# RZT2L register map
Vendor: Renesas Electronics Corporation; Series: RZT; File version: 1.20.00
CPU: other r0p0, little endian, MPU, no FPU, VTOR, 4 interrupt priority bits, 624 interrupts
Registers are 32-bit, read-write, reset 0x0 unless marked. A register's access mark holds for its fields unless they carry their own. Offsets are from the block's base; [hi:lo] are bit positions; lines under a group give offsets from that group; {n}, {i} and the like mark numbered series; 'fields as' and 'values as' point back to an identical list; <NAME> marks a mode.

## GPT7 (part 2 of 2) — General PWM Timer 7
Base 0x80000000
Same registers: GPT8 0x80000100, GPT9 0x80000200, GPT10 0x80000300, GPT11 0x80000400, GPT12 0x80000500, GPT13 0x80000600, GPT0 0x90002000, GPT1 0x90002100, GPT2 0x90002200, GPT3 0x90002300, GPT4 0x90002400, GPT5 0x90002500, GPT6 0x90002600
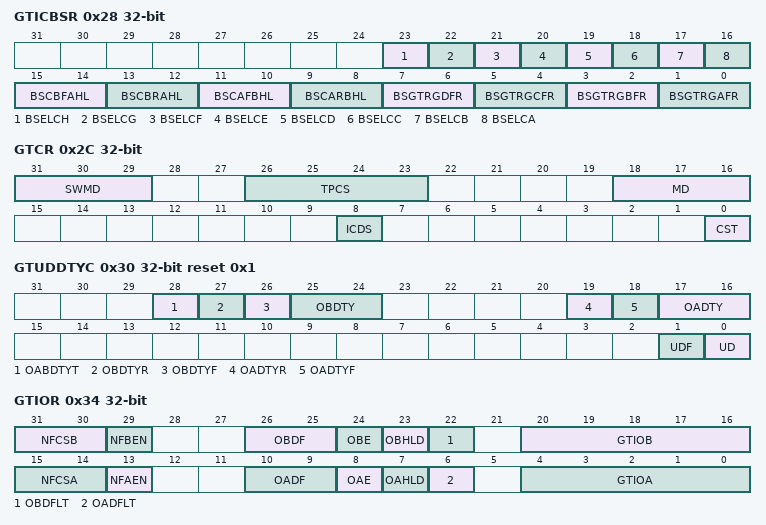
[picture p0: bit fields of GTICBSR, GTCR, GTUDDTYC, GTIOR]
0x28 GTICBSR — General PWM Timer Input Capture Source Select Register B
  [23] BSELCH
    0=Disables GTCCRB input capture by the LLPP GPT event H / NONSAFTY GPT event H input; 1=Enables GTCCRB input capture by the LLPP GPT event H / NONSAFTY GPT event H input
  [22] BSELCG
    0=Disables GTCCRB input capture by the LLPP GPT event G / NONSAFTY GPT event G input; 1=Enables GTCCRB input capture by the LLPP GPT event G / NONSAFTY GPT event G input
  [21] BSELCF
    0=Disables GTCCRB input capture by the LLPP GPT event F / NONSAFTY GPT event F input; 1=Enables GTCCRB input capture by the LLPP GPT event F / NONSAFTY GPT event F input
  [20] BSELCE
    0=Disables GTCCRB input capture by the LLPP GPT event E / NONSAFTY GPT event E input; 1=Enables GTCCRB input capture by the LLPP GPT event E / NONSAFTY GPT event E input
  [19] BSELCD
    0=Disables GTCCRB input capture by the LLPP GPT event D / NONSAFTY GPT event D input; 1=Enables GTCCRB input capture by the LLPP GPT event D / NONSAFTY GPT event D input
  [18] BSELCC
    0=Disables GTCCRB input capture by the LLPP GPT event C / NONSAFTY GPT event C input; 1=Enables GTCCRB input capture by the LLPP GPT event C / NONSAFTY GPT event C input
  [17] BSELCB
    0=Disables GTCCRB input capture by the LLPP GPT event B / NONSAFTY GPT event B input; 1=Enables GTCCRB input capture by the LLPP GPT event B / NONSAFTY GPT event B input
  [16] BSELCA
    0=Disables GTCCRB input capture by the LLPP GPT event A / NONSAFTY GPT event A input; 1=Enables GTCCRB input capture by the LLPP GPT event A / NONSAFTY GPT event A input
  [15:14] BSCBFAHL
    0=Falling edge of the GTIOCnB signal is not used as a trigger to capture the counter value in the GTCCRB register; 1=The counter value is captured in the GTCCRB register at a falling edge of the GTIOCnB signal while the GTIOCnA pin is driven low; 2=The counter value is captured in the GTCCRB register at a falling edge of the GTIOCnB signal while the GTIOCnA pin is driven high; 3=The counter value is captured in the GTCCRB register at a falling edge of the GTIOCnB signal
  [13:12] BSCBRAHL
    0=Rising edge of the GTIOCnB signal is not used as a trigger to capture the counter value in the GTCCRB register; 1=The counter value is captured in the GTCCRB register at a rising edge of the GTIOCnB signal while the GTIOCnA pin is driven low; 2=The counter value is captured in the GTCCRB register at a rising edge of the GTIOCnB signal while the GTIOCnA pin is driven high; 3=The counter value is captured in the GTCCRB register at a rising edge of the GTIOCnB signal
  [11:10] BSCAFBHL
    0=Falling edge of the GTIOCnA signal is not used as a trigger to capture the counter value in the GTCCRB register; 1=The counter value is captured in the GTCCRB register at a falling edge of the GTIOCnA signal while the GTIOCnB pin is driven low; 2=The counter value is captured in the GTCCRB register at a falling edge of the GTIOCnA signal while the GTIOCnB pin is driven high; 3=The counter value is captured in the GTCCRB register at a falling edge of the GTIOCnA signal
  [9:8] BSCARBHL
    0=Rising edge of the GTIOCnA signal is not used as a trigger to capture the counter value in the GTCCRB register; 1=The counter value is captured in the GTCCRB register at a rising edge of the GTIOCnA signal while the GTIOCnB pin is driven low; 2=The counter value is captured in the GTCCRB register at a rising edge of the GTIOCnA signal while the GTIOCnB pin is driven high; 3=The counter value is captured in the GTCCRB register at a rising edge of the GTIOCnA signal
  [7:6] BSGTRGDFR
    0=The GTETRGD signal is not used as a trigger to capture the counter value in the GTCCRB register; 1=The counter value is captured in the GTCCRB register at a rising edge of the GTETRGD signal; 2=The counter value is captured in the GTCCRB register at a falling edge of the GTETRGD signal; 3=The counter value is captured in the GTCCRB register at both edges of the GTETRGD signal
  [5:4] BSGTRGCFR
    0=The GTETRGC signal is not used as a trigger to capture the counter value in the GTCCRB register; 1=The counter value is captured in the GTCCRB register at a rising edge of the GTETRGC signal; 2=The counter value is captured in the GTCCRB register at a falling edge of the GTETRGC signal; 3=The counter value is captured in the GTCCRB register at both edges of the GTETRGC signal
  [3:2] BSGTRGBFR
    0=The GTETRGB signal is not used as a trigger to capture the counter value in the GTCCRB register; 1=The counter value is captured in the GTCCRB register at a rising edge of the GTETRGB signal; 2=The counter value is captured in the GTCCRB register at a falling edge of the GTETRGB signal; 3=The counter value is captured in the GTCCRB register at both edges of the GTETRGB signal
  [1:0] BSGTRGAFR
    0=The GTETRGA signal is not used as a trigger to capture the counter value in the GTCCRB register; 1=The counter value is captured in the GTCCRB register at a rising edge of the GTETRGA signal; 2=The counter value is captured in the GTCCRB register at a falling edge of the GTETRGA signal; 3=The counter value is captured in the GTCCRB register at both edges of the GTETRGA signal
0x2C GTCR — General PWM Timer Control Register
  [31:29] SWMD — Switch Mode Select
    0=Hardware switch operation is disabled; 1=Switch to upcount with offset reload; 2=Switch to downcount with offset reload; 3=Setting prohibited; 4=Setting prohibited; 5=Switch to upcount without offset reload; 6=Switch to downcount without offset reload; 7=Setting prohibited
  [26:23] TPCS — Timer Prescaler Select
    0=Core Clock/1; 1=Core Clock/2; 2=Core Clock/4; 3=Core Clock/8; 4=Core Clock/16; 5=Core Clock/32; 6=Core Clock/64; 7=Setting prohibited; 8=Core Clock/256; 9=Setting prohibited; 10=Core Clock/1024; 11=Setting prohibited; 12=GTETRGA, GTETRGSA for SAFETY group (using the POEG); 13=GTETRGB, GTETRGSB for SAFETY group (using the POEG); 14=GTETRGC (using the POEG) only LLPP and NONSAFTY group; 15=GTETRGD (using the POEG) only LLPP and NONSAFTY group
  [18:16] MD — Mode Select
    0=Sawtooth-wave PWM mode (single buffer or double buffer possible); 1=Sawtooth-wave one-shot pulse mode (fixed buffer operation); 2=Setting prohibited; 3=Setting prohibited; 4=Triangle-wave PWM mode 1 (32-bit transfer at trough) (single buffer or double buffer possible); 5=Triangle-wave PWM mode 2 (32-bit transfer at crest and trough) (single buffer or double buffer possible); 6=Triangle-wave PWM mode 3 (64-bit transfer at trough) (fixed buffer operation); 7=Setting prohibited
  [8] ICDS — Input Capture Operation Select at Count Stop
    0=Input capture is operated during count stop; 1=Input capture is not operated during count stop
  [0] CST — Count Start
    0=Count operation is stopped; 1=Count operation is started
0x30 GTUDDTYC reset 0x1 — General PWM Timer Count Direction and Duty Setting Register
  [28] OABDTYT — GTUDDTYC.OADTY[1:0] and GTUDDTYC.OBDTY[1:0] reflect timing setting in the triangle-wave mode
    0=Reflect GTUDDTYC.OADTY[1:0] and GTUDDTYC.OBDTY[1:0] setting at trough of triangle-wave; 1=Reflect GTUDDTYC.OADTY[1:0] and GTUDDTYC.OBDTY[1:0] setting at trough and crest of triangle-wave
  [27] OBDTYR — Output after Release of GTIOCnB Pin Output 0%/100% Duty Cycle Settings
    0=The function selected by the GTIOR.GTIOB[3:2] bits is applied to the output value when the duty cycle is set after release from the 0 or 100% duty-cycle setting; 1=The function selected by the GTIOR.GTIOB[3:2] bits is applied to the compare match output value which is masked after release from the 0 or 100% duty-cycle setting
  [26] OBDTYF — GTIOCnB Pin Output Duty Forced Setting
    0=Duty of the GTIOCnB pin output is not forcibly set; 1=Duty of the GTIOCnB pin output is forcibly set
  [25:24] OBDTY — GTIOCnB Pin Output Duty Setting
    0b0x=Compare matches determine the duty cycle of the output on the GTIOCnB pin; 2=The duty cycle of the output on the GTIOCnB pin is 0%; 3=The duty cycle of the output on the GTIOCnB pin is 100%
  [19] OADTYR — Output after Release of GTIOCnA Pin Output 0%/100% Duty Cycle Settings
    0=The function selected by the GTIOR.GTIOA[3:2] bits is applied to the output value when the duty cycle is set after release from the 0 or 100% duty-cycle setting; 1=The function selected by the GTIOR.GTIOA[3:2] bits is applied to the compare match output value which is masked after release from the 0 or 100% duty-cycle setting
  [18] OADTYF — GTIOCnA Pin Output Duty Forced Setting
    0=Duty of the GTIOCnA pin output is not forcibly set; 1=Duty of the GTIOCnA pin output is forcibly set
  [17:16] OADTY — GTIOCnA Pin Output Duty Setting
    0b0x=Compare matches determine the duty cycle of the output on the GTIOCnA pin; 2=The duty cycle of the output on the GTIOCnA pin is 0%; 3=The duty cycle of the output on the GTIOCnA pin is 100%
  [1] UDF — Forcible Count Direction Setting
    0=Count direction is not forcibly set; 1=Count direction is forcibly set
  [0] UD — Count Direction Setting
    0=GTCNT counts down; 1=GTCNT counts up
0x34 GTIOR — General PWM Timer I/O Control Register
  [31:30] NFCSB — GTIOCnB Pin Input Noise Filter Sampling Clock Select
    0=Core clock; 1=Core clock/4; 2=Core clock/16; 3=Core clock/64
  [29] NFBEN — GTIOCnB Pin Input Noise Filter Enable
    0=The noise filter for GTIOCnB pin input is disabled; 1=The noise filter for GTIOCnB pin input is enabled
  [26:25] OBDF — GTIOCnB Pin Negate Value Setting
    0=None of the following sources is specified; 1=GTIOCnB pin is placed in the Hi-Z state in response to control for output negation; 2=GTIOCnB pin is set to 0 in response to control for output negation; 3=GTIOCnB pin is set to 1 in response to control for output negation
  [24] OBE — GTIOCnB Pin Output Enable
    0=Pin output is disabled; 1=Pin output is enabled
  [23] OBHLD — GTIOCnB Pin Output Retention at the Start/Stop Count
    0=The GTIOCnB pin output level at start/stop of counting depends on the register setting; 1=The GTIOCnB pin output level is retained at start/stop of counting
  [22] OBDFLT — GTIOCnB Pin Output Value Setting at the Count Stop
    0=The GTIOCnB pin outputs low when counting is stopped; 1=The GTIOCnB pin outputs high when counting is stopped
  [20:16] GTIOB — GTIOCnB Pin Function Select
  [15:14] NFCSA — GTIOCnA Pin Input Noise Filter Sampling Clock Select
    values as NFCSB
  [13] NFAEN — GTIOCnA Pin Input Noise Filter Enable
    0=The noise filter for GTIOCnA pin input is disabled; 1=The noise filter for GTIOCnA pin input is enabled
  [10:9] OADF — GTIOCnA Pin Negate Value Setting
    0=None of the following sources is specified; 1=GTIOCnA pin is placed in the Hi-Z state in response to control for output negation; 2=GTIOCnA pin is set to 0 in response to control for output negation; 3=GTIOCnA pin is set to 1 in response to control for output negation
  [8] OAE — GTIOCnA Pin Output Enable
    0=Pin output is disabled; 1=Pin output is enabled
  [7] OAHLD — GTIOCnA Pin Output Retention at the Start/Stop Count
    0=The GTIOCnA pin output level at start/stop of counting depends on the register setting; 1=The GTIOCnA pin output level is retained at start/stop of counting
  [6] OADFLT — GTIOCnA Pin Output Value Setting at the Count Stop
    0=The GTIOCnA pin outputs low when counting is stopped; 1=The GTIOCnA pin outputs high when counting is stopped
  [4:0] GTIOA — GTIOCnA Pin Function Select
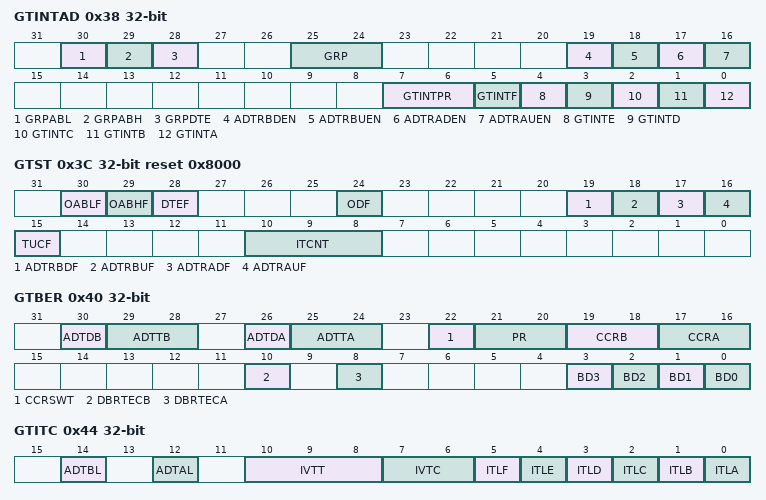
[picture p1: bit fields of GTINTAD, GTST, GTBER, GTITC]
0x38 GTINTAD — General PWM Timer Interrupt Output Setting Register
  [30] GRPABL — (GTIOCnA pin and GTIOCnB output)
    0=Simultaneous low output stop detection is disabled; 1=Simultaneous low output stop detection is enabled
  [29] GRPABH — (GTIOCnA pin and GTIOCnB output)
    0=Simultaneous high output stop detection is disabled; 1=Simultaneous high output stop detection is enabled
  [28] GRPDTE
    0=Dead time error output stop detection is disabled; 1=Dead time error output stop detection is enabled
  [25:24] GRP — Select the group to detect disabling of output (dead-time error or simultaneous driving of outputs to the high or low level) to POEG and to request of disabling of output from POEG.
    0=Group A is selected; 1=Group B is selected; 2=Group C is selected; 3=Group D is selected
  [19] ADTRBDEN
    0=A/D converter start request is disabled; 1=A/D converter start request is enabled
  [18] ADTRBUEN
    values as ADTRBDEN
  [17] ADTRADEN
    values as ADTRBDEN
  [16] ADTRAUEN
    values as ADTRBDEN
  [7:6] GTINTPR
    0=Interrupt request is disabled; 1=In sawtooth-wave mode, interrupt requests are enabled at overflows. In triangle-wave mode, interrupt requests are enabled at crests; 2=In sawtooth-wave mode, interrupt requests are enabled at underflows. In triangle-wave mode, interrupt requests are enabled at troughs; 3=In sawtooth-wave mode, interrupt requests are enabled at both overflows and underflows. In triangle-wave mode, interrupt requests are enabled at both crests and troughs
  [5] GTINTF
    0=Interrupt request is disabled; 1=Interrupt request is enabled
  [4] GTINTE
    values as GTINTF
  [3] GTINTD
    values as GTINTF
  [2] GTINTC
    values as GTINTF
  [1] GTINTB
    values as GTINTF
  [0] GTINTA
    values as GTINTF
0x3C GTST reset 0x8000 — General PWM Timer Status Register
  [30] OABLF ro — Simultaneous Low Output Flag
    0=No simultaneous generation of low output both for the GTIOCA and GTIOCB pins has occurred; 1=A simultaneous generation of low output both for the GTIOCA and GTIOCB pins has occurred
  [29] OABHF ro — Simultaneous High Output Flag
    0=No simultaneous generation of high output both for the GTIOCA and GTIOCB pins has occurred; 1=A simultaneous generation of high output both for the GTIOCA and GTIOCB pins has occurred
  [28] DTEF ro — Dead Time Error Flag
    0=No dead time error has occurred; 1=A dead time error has occurred
  [24] ODF ro — Output Stop Request Flag
    0=No output stop request has occurred; 1=An output stop request has occurred
  [19] ADTRBDF — GTADTRB Register Compare Match (Down-Counting) A/D Converter Start Request Flag
    0=No GTADTRB register compare match has occurred in down-counting; 1=A GTADTRB register compare match has occurred in down-counting
  [18] ADTRBUF — GTADTRB Register Compare Match (Up-Counting) A/D Converter Start Request Flag
    0=No GTADTRB register compare match has occurred in up-counting; 1=A GTADTRB register compare match has occurred in up-counting
  [17] ADTRADF — GTADTRA Register Compare Match (Down-Counting) A/D Converter Start Request Flag
    0=No GTADTRA register compare match has occurred in down-counting; 1=A GTADTRA register compare match has occurred in down-counting
  [16] ADTRAUF — GTADTRA Register Compare Match (Up-Counting) A/D Converter Start Request Flag
    0=No GTADTRA register compare match has occurred in up-counting; 1=A GTADTRA register compare match has occurred in up-counting
  [15] TUCF ro — Count Direction Flag
    0=The GTCNT counter counts downward; 1=The GTCNT counter counts upward
  [10:8] ITCNT ro — GPTn_OVF/GPTn_UDF Interrupt Skipping Count Counter
0x40 GTBER — General PWM Timer Buffer Enable Register
  [30] ADTDB — GTADTRB Register Double Buffer Operation
    0=Single buffer operation (GTADTBRB register -> GTADTRB register); 1=Double buffer operation (GTADTDBRB register -> GTADTBRB register -> GTADTRB register)
  [29:28] ADTTB — GTADTRB Register Buffer Transfer Timing Select
    0=No transfer; 1=(Triangle waves) Transfer at crest (Sawtooth waves) Transfer at underflow (during down-counting), overflow (during up-counting), or counter clearing; 2=(Triangle waves) Transfer at trough (Sawtooth waves) Transfer at underflow (during down-counting), overflow (during up-counting), or counter clearing; 3=(Triangle waves) Transfer at both crest and trough (Sawtooth waves) Transfer at underflow (during down-counting), overflow (during up-counting), or counter clearing
  [26] ADTDA — GTADTRA Register Double Buffer Operation
    0=Single buffer operation (GTADTBRA register -> GTADTRA register); 1=Double buffer operation (GTADTDBRA register -> GTADTBRA register -> GTADTRA register)
  [25:24] ADTTA — GTADTRA Register Buffer Transfer Timing Select
    values as ADTTB
  [22] CCRSWT — GTCCRA and GTCCRB Registers Forcible Buffer Operation
  [21:20] PR — GTPR Register Buffer Operation
    0=Buffer operation is not performed; 1=Single buffer operation (GTPBR register -> GTPR register); 0b1x=Double buffer operation (GTPDBR register -> GTPBR register -> GTPR register)
  [19:18] CCRB — GTCCRB Register Buffer Operation
    0=Buffer operation is not performed; 1=Single buffer operation (GTCCRB register <-> GTCCRE register); 0b1x=Double buffer operation (GTCCRB register <-> GTCCRE register <-> GTCCRF register)
  [17:16] CCRA — GTCCRA Register Buffer Operation
    0=Buffer operation is not performed; 1=Single buffer operation (GTCCRA register <-> GTCCRC register); 0b1x=Double buffer operation (GTCCRA register <-> GTCCRC register <-> GTCCRD register)
  [10] DBRTECB — GTCCRB Register Double Buffer Repeat Operation Enable
    0=GTCCRB register double buffer repeat operation is disabled; 1=GTCCRB register double buffer repeat operation is enabled
  [8] DBRTECA — GTCCRA Register Double Buffer Repeat Operation Enable
    0=GTCCRA register double buffer repeat operation is disabled; 1=GTCCRA register double buffer repeat operation is enabled
  [3] BD3 — GTDVU/GTDVD Registers Buffer Operation Disable
    0=Buffer operation is enabled; 1=Buffer operation is disabled
  [2] BD2 — GTADTRA/GTADTRB Registers Buffer Operation Disable
    values as BD3
  [1] BD1 — GTPR Register Buffer Operation Disable
    values as BD3
  [0] BD0 — GTCCRA/GTCCRB Registers Buffer Operation Disable
    values as BD3
0x44 GTITC — General PWM Timer Interrupt and A/D Converter Start Request Skipping Setting Register
  [14] ADTBL
    0=Not linked with GPTn_OVF/GPTn_UDF interrupt skipping function; 1=Linked with GPTn_OVF/GPTn_UDF interrupt skipping function
  [12] ADTAL
    values as ADTBL
  [10:8] IVTT
    0=Skipping is not performed; {v}=Skipping count of {v} (v=1..7)
  [7:6] IVTC
    0=Skipping is not performed; 1=Both overflow and underflow for sawtooth waves and crest for triangle waves are counted and skipped; 2=Both overflow and underflow for sawtooth waves and trough for triangle waves are counted and skipped; 3=Both overflow and underflow for sawtooth waves and both crest and trough for triangle waves are counted and skipped
  [5] ITLF
    values as ADTBL
  [4] ITLE
    values as ADTBL
  [3] ITLD
    values as ADTBL
  [2] ITLC
    values as ADTBL
  [1] ITLB
    values as ADTBL
  [0] ITLA
    values as ADTBL
0x48 GTCNT — General PWM Timer Counter
0x4C GTCCRA reset 0xFFFFFFFF — General PWM Timer Compare Capture Register A (m = A to F)
0x50 GTCCRB reset 0xFFFFFFFF — General PWM Timer Compare Capture Register B (m = A to F)
0x54 GTCCRC reset 0xFFFFFFFF — General PWM Timer Compare Capture Register C (m = A to F)
0x58 GTCCRE reset 0xFFFFFFFF — General PWM Timer Compare Capture Register E (m = A to F)
0x5C GTCCRD reset 0xFFFFFFFF — General PWM Timer Compare Capture Register D (m = A to F)
0x60 GTCCRF reset 0xFFFFFFFF — General PWM Timer Compare Capture Register F (m = A to F)
0x64 GTPR reset 0xFFFFFFFF — General PWM Timer Cycle Setting Register
0x68 GTPBR reset 0xFFFFFFFF — General PWM Timer Cycle Setting Buffer Register
0x6C GTPDBR reset 0xFFFFFFFF — General PWM Timer Cycle Setting Double-Buffer Register
0x70 GTADTRA reset 0xFFFFFFFF — A/D Converter Start Request Timing Register A (m = A, B)
0x74 GTADTBRA reset 0xFFFFFFFF — A/D Converter Start Request Timing Buffer Register A (m = A, B)
0x78 GTADTDBRA reset 0xFFFFFFFF — A/D Converter Start Request Timing Double-Buffer Register A
0x7C GTADTRB reset 0xFFFFFFFF — A/D Converter Start Request Timing Register B (m = A, B)
0x80 GTADTBRB reset 0xFFFFFFFF — A/D Converter Start Request Timing Buffer Register B (m = A, B)
0x84 GTADTDBRB reset 0xFFFFFFFF — A/D Converter Start Request Timing Double-Buffer Register B
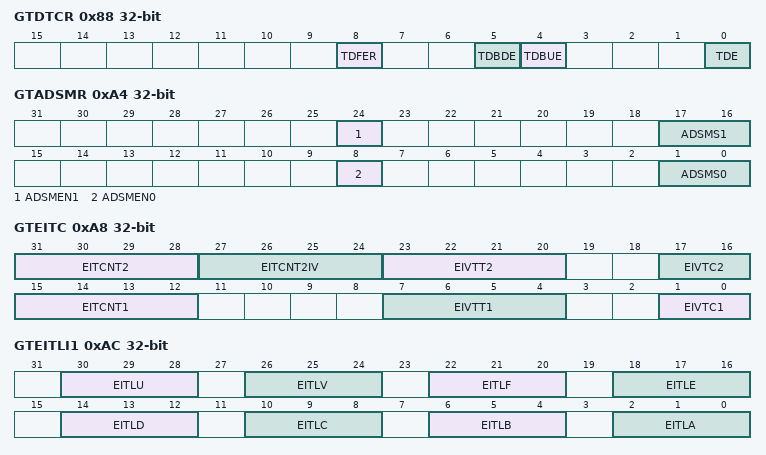
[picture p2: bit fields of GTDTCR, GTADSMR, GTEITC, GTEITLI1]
0x88 GTDTCR — General PWM Timer Dead Time Control Register
  [8] TDFER — GTDVD Register Setting
    0=GTDVU and GTDVD registers are set separately; 1=The value written to GTDVU register is automatically set to GTDVD register
  [5] TDBDE — GTDVD Register Buffer Operation Enable
    0=GTDVD register buffer operation is disabled; 1=GTDVD register buffer operation is enabled
  [4] TDBUE — GTDVU Register Buffer Operation Enable
    0=GTDVU register buffer operation is disabled; 1=GTDVU register buffer operation is enabled
  [0] TDE — Negative-Phase Waveform Setting
    0=GTCCRB register is set without using GTDVU and GTDVD registers; 1=GTDVU and GTDVD registers are used to set the compare match value for negative-phase waveform with dead time automatically in GTCCRB register
0x8C GTDVU reset 0xFFFFFFFF — General PWM Timer Dead Time Value Register U (m = U, D)
0x90 GTDVD reset 0xFFFFFFFF — General PWM Timer Dead Time Value Register D (m = U, D)
0x94 GTDBU reset 0xFFFFFFFF — General PWM Timer Dead Time Value Buffer Register U (m = U, D)
0x98 GTDBD reset 0xFFFFFFFF — General PWM Timer Dead Time Value Buffer Register D (m = U, D)
0x9C GTSOS ro — General PWM Timer Output Protection Function Status Register
  [1:0] SOS — Output Protection Function Status
    0=Normal operation; 1=Protected state (GTCCRA = 0 is set during transfer at trough or crest); 2=Protected state (GTCCRA >= GTPR is set during transfer at trough); 3=Protected state (GTCCRA >= GTPR is set during transfer at crest)
0xA0 GTSOTR — General PWM Timer Output Protection Function Temporary Release Register
  [0] SOTR — Output Protection Function Temporary Release
    0=Protected state is not released; 1=Protected state is released
0xA4 GTADSMR — General PWM Timer A/D Conversion Start Request Signal Monitoring Register
  [24] ADSMEN1 — A/D Conversion Start Request Signal Monitor 1 Output Enabling
    0=Output of A/D conversion start request signal monitor 1 is disabled; 1=Output of A/D conversion start request signal monitor 1 is enabled
  [17:16] ADSMS1 — A/D Conversion Start Request Signal Monitor 1 Selection
    0=A/D conversion start request signal generated by the GTADTRA register during up-counting; 1=A/D conversion start request signal generated by the GTADTRA register during down-counting; 2=A/D conversion start request signal generated by the GTADTRB register during up-counting; 3=A/D conversion start request signal generated by the GTADTRB register during down-counting
  [8] ADSMEN0 — A/D Conversion Start Request Signal Monitor 0 Output Enabling
    0=Output of A/D conversion start request signal monitor 0 is disabled; 1=Output of A/D conversion start request signal monitor 0 is enabled
  [1:0] ADSMS0 — A/D Conversion Start Request Signal Monitor 0 Selection
    values as ADSMS1
0xA8 GTEITC — General PWM Timer Extended Interrupt Skipping Counter Control Register
  [31:28] EITCNT2 ro — Extended Interrupt Skipping Counter 2
  [27:24] EITCNT2IV — Extended Interrupt Skipping Counter 2 Initial Value
  [23:20] EIVTT2 — Extended Interrupt Skipping 2 Skipping Count Setting
  [17:16] EIVTC2 — Extended Interrupt Skipping Counter 2 Count Source Select
    0=Not counted (not skipped); 1=Counting both at overflow or underflow in sawtooth-wave mode and counting crests in triangle-wave mode; 2=Counting both at overflow or underflow in sawtooth-wave mode and counting troughs in triangle-wave mode; 3=Counting both at overflow or underflow in sawtooth-wave mode and counting both crests and troughs in triangle-wave mode
  [15:12] EITCNT1 ro — Extended Interrupt Skipping Counter 1
  [7:4] EIVTT1 — Extended Interrupt Skipping 1 Skipping Count Setting
  [1:0] EIVTC1 — Extended Interrupt Skipping Counter 1 Count Source Select
    values as EIVTC2
0xAC GTEITLI1 — General PWM Timer Extended Interrupt Skipping Setting Register 1
  [30:28] EITLU — Underflow Interrupt Extended Skipping Function Select
  [26:24] EITLV — Overflow Interrupt Extended Skipping Function Select
  [22:20] EITLF — GTCCRF Register Compare Match / Input Capture Interrupt Extended Skipping Function Select
  [18:16] EITLE — GTCCRE Register Compare Match / Input Capture Interrupt Extended Skipping Function Select
  [14:12] EITLD — GTCCRD Register Compare Match / Input Capture Interrupt Extended Skipping Function Select
  [10:8] EITLC — GTCCRC Register Compare Match / Input Capture Interrupt Extended Skipping Function Select
  [6:4] EITLB — GTCCRB Register Compare Match / Input Capture Interrupt Extended Skipping Function Select
  [2:0] EITLA — GTCCRA Register Compare Match / Input Capture Interrupt Extended Skipping Function Select
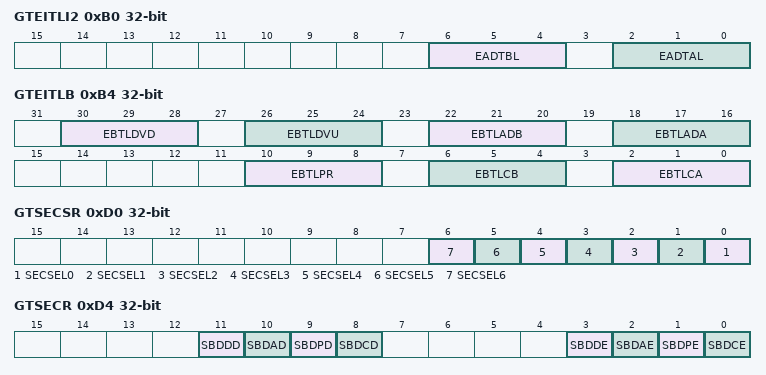
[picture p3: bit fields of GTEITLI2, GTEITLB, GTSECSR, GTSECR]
0xB0 GTEITLI2 — General PWM Timer Extended Interrupt Skipping Setting Register 2
  [6:4] EADTBL — GTADTRB A/D Converter Start Request Extended Skipping Function Select
  [2:0] EADTAL — GTADTRA A/D Converter Start Request Extended Skipping Function Select
0xB4 GTEITLB — General PWM Timer Extended Buffer Transfer Skipping Setting Register
  [30:28] EBTLDVD — GTDVD Register Buffer Transfer Extended Skipping Function Select
  [26:24] EBTLDVU — GTDVU Register Buffer Transfer Extended Skipping Function Select
  [22:20] EBTLADB — GTADTRB Register Buffer Transfer Extended Skipping Function Select
  [18:16] EBTLADA — GTADTRA Register Buffer Transfer Extended Skipping Function Select
  [10:8] EBTLPR — GTPR Register Buffer Transfer Extended Skipping Function Select
  [6:4] EBTLCB — GTCCRB Register Buffer Transfer Extended Skipping Function Select
  [2:0] EBTLCA — GTCCRA Register Buffer Transfer Extended Skipping Function Select
0xD0 GTSECSR — General PWM Timer Operation Enable Bit Simultaneous Control Channel Select Register
  [all] fields
    0=Disable simultaneous control; 1=Enable simultaneous control
  [n] SECSEL{n} (n=0..6) — Channel {n} Operation Enable Bit Simultaneous Control Channel Select
0xD4 GTSECR — General PWM Timer Operation Enable Bit Simultaneous Control Register
  [11] SBDDD — GTDV Register Buffer Operation Simultaneous Disable
    0=Disable simultaneous disabling GTDV buffer operations; 1=Disable GTDV register buffer operations simultaneously
  [10] SBDAD — GTADTR Register Buffer Operation Simultaneous Disable
    0=Disable simultaneous disabling GTADTR buffer operations; 1=Disable GTADTR register buffer operations simultaneously
  [9] SBDPD — GTPR Register Buffer Operation Simultaneous Disable
    0=Disable simultaneous disabling GTPR buffer operations; 1=Disable GTPR register buffer operations simultaneously
  [8] SBDCD — GTCCR Register Buffer Operation Simultaneous Disable
    0=Disable simultaneous disabling GTCCR buffer operations; 1=Disable GTCCR register buffer operations simultaneously
  [3] SBDDE — GTDV Register Buffer Operation Simultaneous Enable
    0=Disable simultaneous enabling GTDV buffer operations; 1=Enable GTDV register buffer operations simultaneously
  [2] SBDAE — GTADTR Register Buffer Operation Simultaneous Enable
    0=Disable simultaneous enabling GTADTR buffer operations; 1=Enable GTADTR register buffer operations simultaneously
  [1] SBDPE — GTPR Register Buffer Operation Simultaneous Enable
    0=Disable simultaneous enabling GTPR buffer operations; 1=Enable GTPR register buffer operations simultaneously
  [0] SBDCE — GTCCR Register Buffer Operation Simultaneous Enable
    0=Disable simultaneous enabling GTCCR buffer operations; 1=Enable GTCCR register buffer operations simultaneously
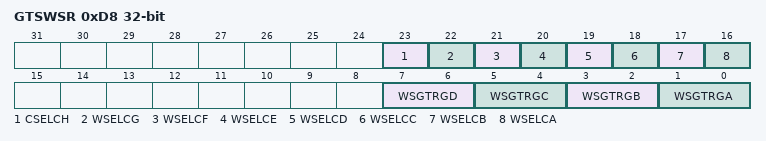
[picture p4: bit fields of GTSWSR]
0xD8 GTSWSR — General PWM Timer Switch Source Select Register
  [23] CSELCH — Event Source Counter Switch Enable
    0=Disables count switch by the LLPP GPT event H / NONSAFTY GPT event H input; 1=Enables count switch by the LLPP GPT event H / NONSAFTY GPT event H input
  [22] WSELCG — Event Source Counter Switch Enable
    0=Disables count switch by the LLPP GPT event G / NONSAFTY GPT event G input; 1=Enables count switch by the LLPP GPT event G / NONSAFTY GPT event G input
  [21] WSELCF — Event Source Counter Switch Enable
    0=Disables count switch by the LLPP GPT event F / NONSAFTY GPT event F input; 1=Enables count switch by the LLPP GPT event F / NONSAFTY GPT event F input
  [20] WSELCE — Event Source Counter Switch Enable
    0=Disables count switch by the LLPP GPT event E / NONSAFTY GPT event E input; 1=Enables count switch by the LLPP GPT event E / NONSAFTY GPT event E input
  [19] WSELCD — Event Source Counter Switch Enable
    0=Disables count switch by the LLPP GPT event D / NONSAFTY GPT event D input; 1=Enables count switch by the LLPP GPT event D / NONSAFTY GPT event D input
  [18] WSELCC — Event Source Counter Switch Enable
    0=Disables count switch by the LLPP GPT event C / NONSAFTY GPT event C input; 1=Enables count switch by the LLPP GPT event C / NONSAFTY GPT event C input
  [17] WSELCB — Event Source Counter Switch Enable
    0=Disables count switch by the LLPP GPT event B / NONSAFTY GPT event B input; 1=Enables count switch by the LLPP GPT event B / NONSAFTY GPT event B input
  [16] WSELCA — Event Source Counter Switch Enable
    0=Disables count switch by the LLPP GPT event A / NONSAFTY GPT event A input; 1=Enables count switch by the LLPP GPT event A / NONSAFTY GPT event A input
  [7:6] WSGTRGD — GTETRGD Signal Edge Select to Switch Counter (GTETRGSD Signal for SAFTY)
    0=The GTETRGD signal is not used as a trigger to switch the counter; 1=The counter is switched at a rising edge of the GTETRGD signal; 2=The counter is switched at a falling edge of the GTETRGD signal; 3=The counter is switched at both edges of the GTETRGD signal
  [5:4] WSGTRGC — GTETRGC Signal Edge Select to Switch Counter (GTETRGSC Signal for SAFTY)
    0=The GTETRGC signal is not used as a trigger to switch the counter; 1=The counter is switched at a rising edge of the GTETRGC signal; 2=The counter is switched at a falling edge of the GTETRGC signal; 3=The counter is switched at both edges of the GTETRGC signal
  [3:2] WSGTRGB — GTETRGB Signal Edge Select to Switch Counter (GTETRGSB Signal for SAFTY)
    0=The GTETRGB signal is not used as a trigger to switch the counter; 1=The counter is switched at a rising edge of the GTETRGB signal; 2=The counter is switched at a falling edge of the GTETRGB signal; 3=The counter is switched at both edges of the GTETRGB signal
  [1:0] WSGTRGA — GTETRGA Signal Edge Select to Switch Counter (GTETRGSA Signal for SAFTY)
    0=The GTETRGA signal is not used as a trigger to switch the counter; 1=The counter is switched at a rising edge of the GTETRGA signal; 2=The counter is switched at a falling edge of the GTETRGA signal; 3=The counter is switched at both edges of the GTETRGA signal
0xDC GTSWOS — General PWM Timer Switch Offset Setting Register

## GPT14 (part 2 of 2) — General PWM Timer 14
Base 0x81000000
Same registers: GPT15 0x81000100, GPT16 0x81000200, GPT17 0x81000300
Registers as GPT7, without GTADTRA, GTADTBRA, GTADTDBRA, GTADTRB, GTADTBRB, GTADTDBRB, GTADSMR.
